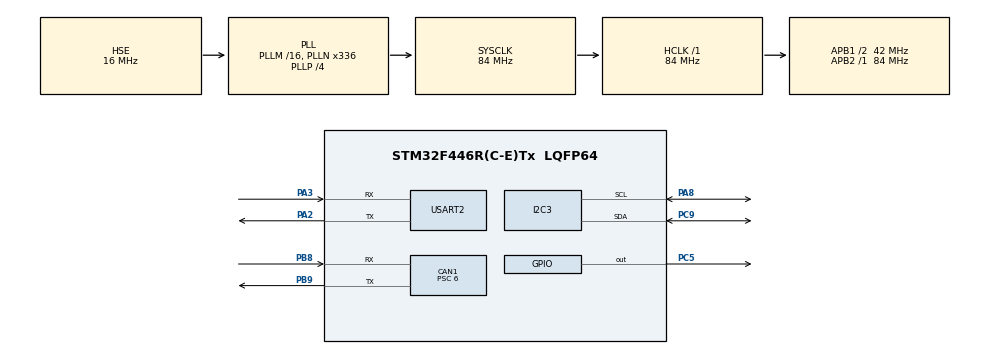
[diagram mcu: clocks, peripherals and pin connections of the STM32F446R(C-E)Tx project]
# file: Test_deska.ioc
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CAN1.ABOM=ENABLE
CAN1.BS1=CAN_BS1_11TQ
CAN1.BS2=CAN_BS2_2TQ
CAN1.CalculateBaudRate=500000
CAN1.CalculateTimeBit=2000
CAN1.CalculateTimeQuantum=142.85714285714286
CAN1.NART=ENABLE
CAN1.Prescaler=6
Dma.I2C3_RX.0.Direction=DMA_PERIPH_TO_MEMORY
Dma.I2C3_RX.0.FIFOMode=DMA_FIFOMODE_DISABLE
Dma.I2C3_RX.0.Instance=DMA1_Stream1
Dma.I2C3_RX.0.MemDataAlignment=DMA_MDATAALIGN_BYTE
Dma.I2C3_RX.0.MemInc=DMA_MINC_ENABLE
Dma.I2C3_RX.0.Mode=DMA_NORMAL
Dma.I2C3_RX.0.PeriphDataAlignment=DMA_PDATAALIGN_BYTE
Dma.I2C3_RX.0.PeriphInc=DMA_PINC_DISABLE
Dma.I2C3_RX.0.Priority=DMA_PRIORITY_HIGH
Dma.Request0=I2C3_RX
I2C3.I2C_Mode=I2C_Fast
Mcu.Family=STM32F4
Mcu.Name=STM32F446R(C-E)Tx
Mcu.Package=LQFP64
NVIC.CAN1_RX0_IRQn=true\:0\:0\:false\:false\:true\:true\:true\:true
NVIC.DMA1_Stream1_IRQn=true\:0\:0\:false\:false\:true\:false\:true\:true
NVIC.I2C3_ER_IRQn=true\:0\:0\:false\:false\:true\:true\:true\:true
NVIC.I2C3_EV_IRQn=true\:0\:0\:false\:false\:true\:true\:true\:true
NVIC.PriorityGroup=NVIC_PRIORITYGROUP_4
NVIC.TIM6_DAC_IRQn=true\:0\:0\:false\:false\:true\:true\:true\:true
PA11.Signal=USB_OTG_FS_DM
PA13.Mode=Serial_Wire
PA13.Signal=SYS_JTMS-SWDIO
PA14.Mode=Serial_Wire
PA14.Signal=SYS_JTCK-SWCLK
PA2.Mode=Asynchronous
PA2.Signal=USART2_TX
PA3.Mode=Asynchronous
PA3.Signal=USART2_RX
PA8.Mode=I2C
PA8.Signal=I2C3_SCL
PB8.Mode=CAN_Activate
PB8.Signal=CAN1_RX
PB9.Mode=CAN_Activate
PB9.Signal=CAN1_TX
PC5.GPIO_Speed=GPIO_SPEED_FREQ_HIGH
PC5.Signal=GPIO_Output
PC9.Mode=I2C
PC9.Signal=I2C3_SDA
PH0-OSC_IN.Mode=HSE-External-Oscillator
PH0-OSC_IN.Signal=RCC_OSC_IN
PH1-OSC_OUT.Mode=HSE-External-Oscillator
PH1-OSC_OUT.Signal=RCC_OSC_OUT
ProjectManager.HeapSize=0x200
ProjectManager.StackSize=0x400
ProjectManager.TargetToolchain=STM32CubeIDE
RCC.AHBFreq_Value=84000000
RCC.APB1CLKDivider=RCC_HCLK_DIV2
RCC.APB1Freq_Value=42000000
RCC.APB1TimFreq_Value=84000000
RCC.APB2Freq_Value=84000000
RCC.APB2TimFreq_Value=84000000
RCC.CortexFreq_Value=84000000
RCC.HCLKFreq_Value=84000000
RCC.HSE_VALUE=16000000
RCC.PLLN=336
RCC.PLLP=RCC_PLLP_DIV4
RCC.PLLQ=7
RCC.PLLSourceVirtual=RCC_PLLSOURCE_HSE
RCC.SYSCLKFreq_VALUE=84000000
RCC.SYSCLKSource=RCC_SYSCLKSOURCE_PLLCLK
RCC.USBFreq_Value=48000000
RCC.VCOOutputFreq_Value=336000000
TIM10.AutoReloadPreload=TIM_AUTORELOAD_PRELOAD_ENABLE
TIM10.Prescaler=8399
TIM6.AutoReloadPreload=TIM_AUTORELOAD_PRELOAD_ENABLE
TIM6.Period=499
TIM6.Prescaler=839
USART2.VirtualMode=VM_ASYNC
VP_TIM10_VS_ClockSourceINT.Mode=Enable_Timer
VP_TIM6_VS_ClockSourceINT.Mode=Enable_Timer
board=custom

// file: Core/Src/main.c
/* USER CODE BEGIN Header */
/**
  ******************************************************************************
  * @file           : main.c
  * @brief          : Main program body
  ******************************************************************************
  * @attention
  *
  * Copyright (c) 2026 STMicroelectronics.
  * All rights reserved.
  *
  * This software is licensed under terms that can be found in the LICENSE file
  * in the root directory of this software component.
  * If no LICENSE file comes with this software, it is provided AS-IS.
  *
  ******************************************************************************
  */
/* USER CODE END Header */
#include "main.h"

CAN_HandleTypeDef hcan1;

I2C_HandleTypeDef hi2c3;
DMA_HandleTypeDef hdma_i2c3_rx;

TIM_HandleTypeDef htim6;
TIM_HandleTypeDef htim10;

UART_HandleTypeDef huart2;

void SystemClock_Config(void);
static void MX_GPIO_Init(void);
static void MX_DMA_Init(void);
static void MX_USART2_UART_Init(void);
static void MX_CAN1_Init(void);
static void MX_I2C3_Init(void);
static void MX_TIM6_Init(void);
static void MX_TIM10_Init(void);

int main(void)
{

  /* MCU Configuration--------------------------------------------------------*/

  /* Reset of all peripherals, Initializes the Flash interface and the Systick. */
  HAL_Init();

  /* Configure the system clock */
  SystemClock_Config();

  /* Initialize all configured peripherals */
  MX_GPIO_Init();
  MX_DMA_Init();
  MX_USART2_UART_Init();
  MX_CAN1_Init();
  MX_I2C3_Init();
  MX_TIM6_Init();
  MX_TIM10_Init();

  /* Infinite loop */
  /* USER CODE BEGIN WHILE */
  while (1)
  {
	  uint8_t value = 5;
	  HAL_UART_Transmit(&huart2, &value, 1, 100);
    /* USER CODE END WHILE */

  }
}

void SystemClock_Config(void)
{
  RCC_OscInitTypeDef RCC_OscInitStruct = {0};
  RCC_ClkInitTypeDef RCC_ClkInitStruct = {0};

  /** Configure the main internal regulator output voltage
  */
  __HAL_RCC_PWR_CLK_ENABLE();
  __HAL_PWR_VOLTAGESCALING_CONFIG(PWR_REGULATOR_VOLTAGE_SCALE3);

  /** Initializes the RCC Oscillators according to the specified parameters
  * in the RCC_OscInitTypeDef structure.
  */
  RCC_OscInitStruct.OscillatorType = RCC_OSCILLATORTYPE_HSE;
  RCC_OscInitStruct.HSEState = RCC_HSE_ON;
  RCC_OscInitStruct.PLL.PLLState = RCC_PLL_ON;
  RCC_OscInitStruct.PLL.PLLSource = RCC_PLLSOURCE_HSE;
  RCC_OscInitStruct.PLL.PLLM = 16;
  RCC_OscInitStruct.PLL.PLLN = 336;
  RCC_OscInitStruct.PLL.PLLP = RCC_PLLP_DIV4;
  RCC_OscInitStruct.PLL.PLLQ = 7;
  RCC_OscInitStruct.PLL.PLLR = 2;
  if (HAL_RCC_OscConfig(&RCC_OscInitStruct) != HAL_OK)
  {
    Error_Handler();
  }

  /** Initializes the CPU, AHB and APB buses clocks
  */
  RCC_ClkInitStruct.ClockType = RCC_CLOCKTYPE_HCLK|RCC_CLOCKTYPE_SYSCLK
                              |RCC_CLOCKTYPE_PCLK1|RCC_CLOCKTYPE_PCLK2;
  RCC_ClkInitStruct.SYSCLKSource = RCC_SYSCLKSOURCE_PLLCLK;
  RCC_ClkInitStruct.AHBCLKDivider = RCC_SYSCLK_DIV1;
  RCC_ClkInitStruct.APB1CLKDivider = RCC_HCLK_DIV2;
  RCC_ClkInitStruct.APB2CLKDivider = RCC_HCLK_DIV1;

  if (HAL_RCC_ClockConfig(&RCC_ClkInitStruct, FLASH_LATENCY_2) != HAL_OK)
  {
    Error_Handler();
  }
}

static void MX_CAN1_Init(void)
{

  hcan1.Instance = CAN1;
  hcan1.Init.Prescaler = 6;
  hcan1.Init.Mode = CAN_MODE_NORMAL;
  hcan1.Init.SyncJumpWidth = CAN_SJW_1TQ;
  hcan1.Init.TimeSeg1 = CAN_BS1_11TQ;
  hcan1.Init.TimeSeg2 = CAN_BS2_2TQ;
  hcan1.Init.TimeTriggeredMode = DISABLE;
  hcan1.Init.AutoBusOff = ENABLE;
  hcan1.Init.AutoWakeUp = DISABLE;
  hcan1.Init.AutoRetransmission = ENABLE;
  hcan1.Init.ReceiveFifoLocked = DISABLE;
  hcan1.Init.TransmitFifoPriority = DISABLE;
  if (HAL_CAN_Init(&hcan1) != HAL_OK)
  {
    Error_Handler();
  }

}

static void MX_I2C3_Init(void)
{

  hi2c3.Instance = I2C3;
  hi2c3.Init.ClockSpeed = 400000;
  hi2c3.Init.DutyCycle = I2C_DUTYCYCLE_2;
  hi2c3.Init.OwnAddress1 = 0;
  hi2c3.Init.AddressingMode = I2C_ADDRESSINGMODE_7BIT;
  hi2c3.Init.DualAddressMode = I2C_DUALADDRESS_DISABLE;
  hi2c3.Init.OwnAddress2 = 0;
  hi2c3.Init.GeneralCallMode = I2C_GENERALCALL_DISABLE;
  hi2c3.Init.NoStretchMode = I2C_NOSTRETCH_DISABLE;
  if (HAL_I2C_Init(&hi2c3) != HAL_OK)
  {
    Error_Handler();
  }

}

static void MX_TIM6_Init(void)
{

  TIM_MasterConfigTypeDef sMasterConfig = {0};

  htim6.Instance = TIM6;
  htim6.Init.Prescaler = 839;
  htim6.Init.CounterMode = TIM_COUNTERMODE_UP;
  htim6.Init.Period = 499;
  htim6.Init.AutoReloadPreload = TIM_AUTORELOAD_PRELOAD_ENABLE;
  if (HAL_TIM_Base_Init(&htim6) != HAL_OK)
  {
    Error_Handler();
  }
  sMasterConfig.MasterOutputTrigger = TIM_TRGO_RESET;
  sMasterConfig.MasterSlaveMode = TIM_MASTERSLAVEMODE_DISABLE;
  if (HAL_TIMEx_MasterConfigSynchronization(&htim6, &sMasterConfig) != HAL_OK)
  {
    Error_Handler();
  }

}

static void MX_TIM10_Init(void)
{

  htim10.Instance = TIM10;
  htim10.Init.Prescaler = 8399;
  htim10.Init.CounterMode = TIM_COUNTERMODE_UP;
  htim10.Init.Period = 65535;
  htim10.Init.ClockDivision = TIM_CLOCKDIVISION_DIV1;
  htim10.Init.AutoReloadPreload = TIM_AUTORELOAD_PRELOAD_ENABLE;
  if (HAL_TIM_Base_Init(&htim10) != HAL_OK)
  {
    Error_Handler();
  }

}

static void MX_USART2_UART_Init(void)
{

  huart2.Instance = USART2;
  huart2.Init.BaudRate = 115200;
  huart2.Init.WordLength = UART_WORDLENGTH_8B;
  huart2.Init.StopBits = UART_STOPBITS_1;
  huart2.Init.Parity = UART_PARITY_NONE;
  huart2.Init.Mode = UART_MODE_TX_RX;
  huart2.Init.HwFlowCtl = UART_HWCONTROL_NONE;
  huart2.Init.OverSampling = UART_OVERSAMPLING_16;
  if (HAL_UART_Init(&huart2) != HAL_OK)
  {
    Error_Handler();
  }

}

static void MX_DMA_Init(void)
{

  /* DMA controller clock enable */
  __HAL_RCC_DMA1_CLK_ENABLE();

  /* DMA interrupt init */
  /* DMA1_Stream1_IRQn interrupt configuration */
  HAL_NVIC_SetPriority(DMA1_Stream1_IRQn, 0, 0);
  HAL_NVIC_EnableIRQ(DMA1_Stream1_IRQn);

}

static void MX_GPIO_Init(void)
{
  GPIO_InitTypeDef GPIO_InitStruct = {0};

  /* GPIO Ports Clock Enable */
  __HAL_RCC_GPIOH_CLK_ENABLE();
  __HAL_RCC_GPIOA_CLK_ENABLE();
  __HAL_RCC_GPIOC_CLK_ENABLE();
  __HAL_RCC_GPIOB_CLK_ENABLE();

  /*Configure GPIO pin Output Level */
  HAL_GPIO_WritePin(GPIOC, GPIO_PIN_5, GPIO_PIN_RESET);

  /*Configure GPIO pin : PC5 */
  GPIO_InitStruct.Pin = GPIO_PIN_5;
  GPIO_InitStruct.Mode = GPIO_MODE_OUTPUT_PP;
  GPIO_InitStruct.Pull = GPIO_NOPULL;
  GPIO_InitStruct.Speed = GPIO_SPEED_FREQ_HIGH;
  HAL_GPIO_Init(GPIOC, &GPIO_InitStruct);

  /*Configure GPIO pin : PA11 */
  GPIO_InitStruct.Pin = GPIO_PIN_11;
  GPIO_InitStruct.Mode = GPIO_MODE_AF_PP;
  GPIO_InitStruct.Pull = GPIO_NOPULL;
  GPIO_InitStruct.Speed = GPIO_SPEED_FREQ_VERY_HIGH;
  GPIO_InitStruct.Alternate = GPIO_AF10_OTG_FS;
  HAL_GPIO_Init(GPIOA, &GPIO_InitStruct);

}

void Error_Handler(void)
{
  __disable_irq();
  while (1)
  {
  }
}
